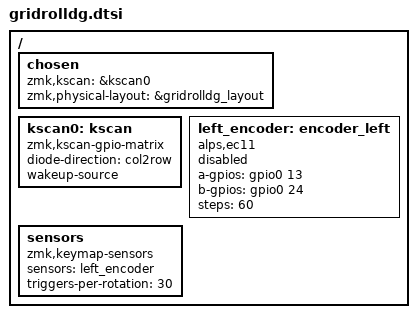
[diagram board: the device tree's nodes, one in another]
/* SPDX-License-Identifier: MIT */
#include <dt-bindings/zmk/matrix_transform.h>
#include "gridrolldg-layouts.dtsi"

/ {
    chosen {
        zmk,kscan = &kscan0;
        zmk,physical-layout = &gridrolldg_layout;
    };
    kscan0: kscan {
        compatible = "zmk,kscan-gpio-matrix";
        diode-direction = "col2row";
        wakeup-source;
    };
    left_encoder: encoder_left {
        compatible = "alps,ec11";
        a-gpios = <&gpio0 13 (GPIO_ACTIVE_HIGH | GPIO_PULL_UP)>;
        b-gpios = <&gpio0 24 (GPIO_ACTIVE_HIGH | GPIO_PULL_UP)>;
        steps = <60>;
        status = "disabled";
    };
    sensors: sensors {
        compatible = "zmk,keymap-sensors";
        sensors = <&left_encoder>;
        triggers-per-rotation = <30>;
    };
};
